# MM32F013x register map
File version: 1.01
CPU: CM0 r0p0, little endian, no MPU, no FPU, 2 interrupt priority bits
Registers are 32-bit, read-write, reset 0x0 unless marked. A register's access mark holds for its fields unless they carry their own. Offsets are from the block's base; [hi:lo] are bit positions.

## RTC — Real time clock
Base 0x40002800
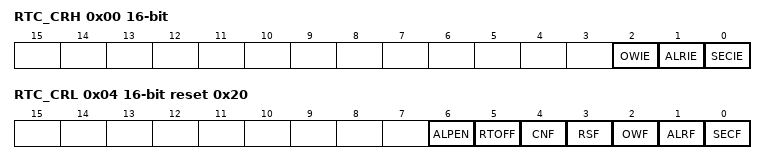
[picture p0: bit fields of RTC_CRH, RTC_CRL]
0x00 RTC_CRH 16-bit — RTC configuration high register
  [2] OWIE — Overflow interrupt enable
  [1] ALRIE — Alarm interrupt enable
  [0] SECIE — Second interrupt enable
0x04 RTC_CRL 16-bit reset 0x20 — RTC configuration low register
  [6] ALPEN — RTC alarm loop enable
  [5] RTOFF — RTC operation OFF
  [4] CNF — Configuration flag
  [3] RSF — Registers synchronized flag
  [2] OWF — Overflow flag
  [1] ALRF — Alarm flag
  [0] SECF — Second flag
0x08 RTC_PRLH 16-bit wo — RTC Prescaler load high register
  [3:0] PRL — RTC prescaler reload value high
0x0C RTC_PRLL 16-bit wo — RTC Prescaler load low register
  [15:0] PRL — RTC prescaler reload value low
0x10 RTC_DIVH 16-bit ro — RTC prescaler divider factor high register
  [3:0] DIV — RTC clock divider high
0x14 RTC_DIVL 16-bit ro — RTC prescaler divider factor low register
  [15:0] DIV — RTC clock divider low
0x18 RTC_CNTH 16-bit — RTC counter high register
  [15:0] CNT — RTC counter high
0x1C RTC_CNTL 16-bit — RTC counter low register
  [15:0] CNT — RTC counter low
0x20 RTC_ALRH 16-bit reset 0xFFFF — RTC alarm high register
  [15:0] ALR — RTC alarm high
0x24 RTC_ALRL 16-bit reset 0xFFFF — RTC alarm low register
  [15:0] ALR — RTC alarm low
0x28 RTC_MSRH 16-bit — RTC millisecond alarm high register
  [3:0] MSR — RTC msec high
0x2C RTC_MSRL 16-bit — RTC millisecond alarm low register
  [15:0] MSR — RTC msec low

## SPI1 — Serial peripheral interface
Base 0x40013000
Same registers: SPI2 0x40003800
0x00 TXREG
  [31:0] TXREG — Transmit data register
0x04 RXREG ro
  [31:0] RXREG — Receive data register
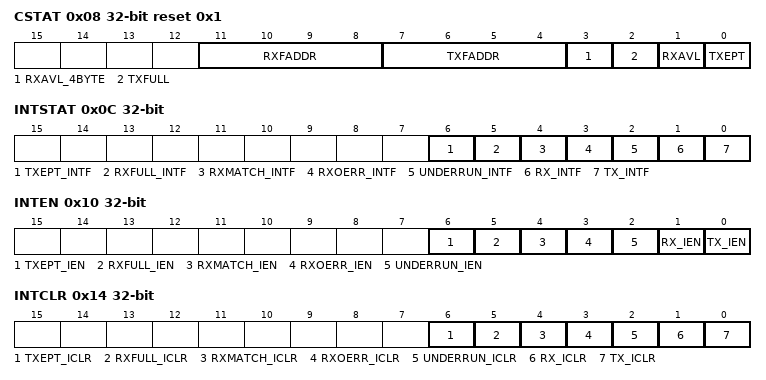
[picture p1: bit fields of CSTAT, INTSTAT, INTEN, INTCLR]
0x08 CSTAT ro reset 0x1
  [11:8] RXFADDR — Transmit FIFO address
  [7:4] TXFADDR — Receive FIFO address
  [3] RXAVL_4BYTE — Receive available 4 byte data message
  [2] TXFULL — Transmitter FIFO full status bit
  [1] RXAVL — Receive available byte data message
  [0] TXEPT — Transmitter empty bit
0x0C INTSTAT
  [6] TXEPT_INTF — Transmitter empty interrupt flag bit
  [5] RXFULL_INTF — RX FIFO full interrupt flag bit
  [4] RXMATCH_INTF — Receive data match the RXDNR number
  [3] RXOERR_INTF — Receive overrun error interrupt flag bit
  [2] UNDERRUN_INTF — SPI underrun interrupt flag bit
  [1] RX_INTF — Receive data available interrupt flag bit
  [0] TX_INTF — Transmit FIFO avialable interrupt flag bit
0x10 INTEN
  [6] TXEPT_IEN — Transmit empty interrupt enable bit
  [5] RXFULL_IEN — Receive FIFO full interrupt enable bit
  [4] RXMATCH_IEN — Receive data complete interrupt enable bit
  [3] RXOERR_IEN — Overrun error interrupt enable bit
  [2] UNDERRUN_IEN — Transmitter underrun interrupt enable bit(SPI slave mode only)
  [1] RX_IEN — Receive FIFO interrupt enable bit
  [0] TX_IEN — Transmit FIFO empty interrupt enable bit
0x14 INTCLR
  [6] TXEPT_ICLR — Transmitter empty interrupt clear bit
  [5] RXFULL_ICLR — Receiver buffer full interrupt clear bit
  [4] RXMATCH_ICLR — Receive completed interrupt clear bit
  [3] RXOERR_ICLR — Overrun error interrupt clear bit
  [2] UNDERRUN_ICLR — Transmitter underrun interrupt clear bit(SPI slave mode only)
  [1] RX_ICLR — Receive interrupt clear bit
  [0] TX_ICLR — Transmitter FIFO empty interrupt clear bit
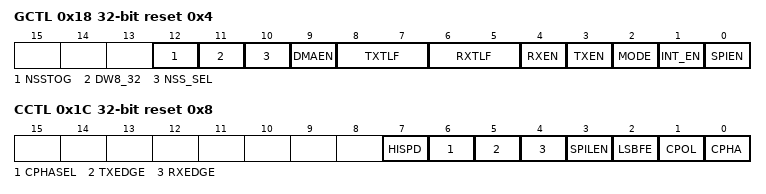
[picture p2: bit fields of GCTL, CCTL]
0x18 GCTL reset 0x4
  [12] NSSTOG — NSS selection signal is automatically flipped
  [11] DW8_32 — Valid byte or double-word data select signal
  [10] NSS_SEL — NSS select signal that from software and hardware
  [9] DMAEN — DMA access mode enable
  [8:7] TXTLF — TX FIFO trigger level bit
  [6:5] RXTLF — RX FIFO trigger level bit
  [4] RXEN — Receive enable bit
  [3] TXEN — Transmit enable bit
  [2] MODE — Master mode bit
  [1] INT_EN — SPI interrupt enable bit
  [0] SPIEN — SPI select bit
0x1C CCTL reset 0x8
  [7] HISPD — High speed slave mode
  [6] CPHASEL — CPHA polarity select
  [5] TXEDGE — Transmit data edge select
  [4] RXEDGE — Receive data edge select
  [3] SPILEN — SPI character length bit
  [2] LSBFE — LSI first enable bit
  [1] CPOL — Clock polarity select bit
  [0] CPHA — Clock phase select bit
0x20 SPBRG reset 0x2
  [15:0] SPBRG — SPI baud rate control register for baud rate
0x24 RXDNR reset 0x1
  [15:0] RXDNR — The register is used to hold a count of to be received bytes in next receive process
0x28 NSSR reset 0xFF
  [0] NSS — Chip select output signal in Master mode
0x2C EXTCTL reset 0x8
  [4:0] EXTLEN — Control SPI data length
